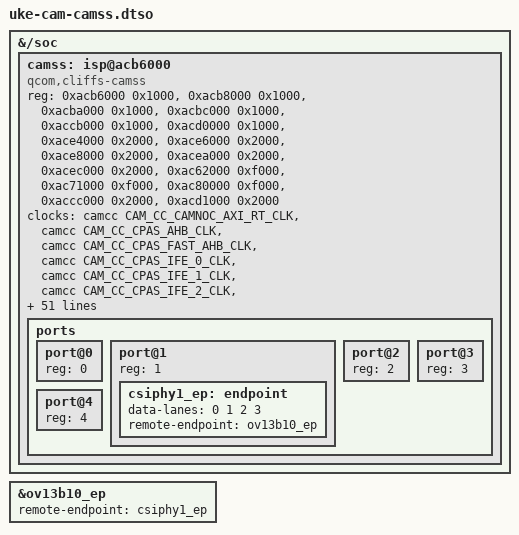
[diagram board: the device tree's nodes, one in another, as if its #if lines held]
// SPDX-License-Identifier: BSD-3-Clause
/*
 * uke-cam-camss.dtso -- C5: CAMSS (CSIPHY/CSID/VFE) de la uke con el driver mainline qcom-camss, recurso "qcom,cliffs-camss"
 * (copia parcheada: module/uke_camss, sin ICC y con 5 CSIPHY). Plan: CAMARAS-PLAN-20261019.md. C0, 19-oct-2026: compila y se aplica
 * con fdtoverlay (tras uke-cam-camcc y uke-cam-rear) en el PC; NO probado en la tablet.
 *
 * El mapa de la uke == el de sm8650 (medido, 19-oct): csid_wrapper acb6000; csid0/1/2 acb8000/acba000/acbc000; lite acca000->accb000,
 * acd0000; csiphy0..4 ace4000..acec000; vfe0/1/2 ac62000/ac71000/ac80000; IRQs SPI 601,603,431,605,376,477,478,479,448,122,602,604,688,606,377
 * (identicas a sm8650.dtsi); SMMU SIDs 0x800/0x20 (IFE), 0x18a0/0x40 (JPEG), 0x1860/0 (CDM). La uke NO tiene csiphy5 (acee000).
 * Sin `interconnects`: la capa ICC cliffs de senemos es solo USB/display (no hay MASTER_CAMNOC_HF) => el modulo parcheado usa 0 rutas ICC.
 * Enlace con el sensor: csiphy1 <-> ov13b10_ep (uke-cam-rear). Rieles CSIPHY = pmxr2230_l2 (0,9 V) y l4 (1,2 V) para los tres grupos.
 */
#include <dt-bindings/clock/qcom,gcc-cliffs.h>
#include <dt-bindings/clock/qcom,sm8650-camcc.h>
#include <dt-bindings/interrupt-controller/arm-gic.h>
#include <dt-bindings/interrupt-controller/irq.h>
/dts-v1/;
/plugin/;

/ {
	fragment@0 {
		target-path = "/soc";

		__overlay__ {
			camss: isp@acb6000 {
				compatible = "qcom,cliffs-camss";
				reg = <0xacb6000 0x1000>, <0xacb8000 0x1000>, <0xacba000 0x1000>, <0xacbc000 0x1000>,
				      <0xaccb000 0x1000>, <0xacd0000 0x1000>,
				      <0xace4000 0x2000>, <0xace6000 0x2000>, <0xace8000 0x2000>, <0xacea000 0x2000>, <0xacec000 0x2000>,
				      <0xac62000 0xf000>, <0xac71000 0xf000>, <0xac80000 0xf000>,
				      <0xaccc000 0x2000>, <0xacd1000 0x2000>;
				reg-names = "csid_wrapper", "csid0", "csid1", "csid2", "csid_lite0", "csid_lite1",
					    "csiphy0", "csiphy1", "csiphy2", "csiphy3", "csiphy4",
					    "vfe0", "vfe1", "vfe2", "vfe_lite0", "vfe_lite1";

				clocks = <&camcc CAM_CC_CAMNOC_AXI_RT_CLK>,
					 <&camcc CAM_CC_CPAS_AHB_CLK>,
					 <&camcc CAM_CC_CPAS_FAST_AHB_CLK>,
					 <&camcc CAM_CC_CPAS_IFE_0_CLK>,
					 <&camcc CAM_CC_CPAS_IFE_1_CLK>,
					 <&camcc CAM_CC_CPAS_IFE_2_CLK>,
					 <&camcc CAM_CC_CPAS_IFE_LITE_CLK>,
					 <&camcc CAM_CC_CSID_CLK>,
					 <&camcc CAM_CC_CSIPHY0_CLK>, <&camcc CAM_CC_CSI0PHYTIMER_CLK>,
					 <&camcc CAM_CC_CSIPHY1_CLK>, <&camcc CAM_CC_CSI1PHYTIMER_CLK>,
					 <&camcc CAM_CC_CSIPHY2_CLK>, <&camcc CAM_CC_CSI2PHYTIMER_CLK>,
					 <&camcc CAM_CC_CSIPHY3_CLK>, <&camcc CAM_CC_CSI3PHYTIMER_CLK>,
					 <&camcc CAM_CC_CSIPHY4_CLK>, <&camcc CAM_CC_CSI4PHYTIMER_CLK>,
					 <&camcc CAM_CC_CSID_CSIPHY_RX_CLK>,
					 <&gcc GCC_CAMERA_HF_AXI_CLK>,
					 <&camcc CAM_CC_QDSS_DEBUG_XO_CLK>,
					 <&camcc CAM_CC_IFE_0_CLK>, <&camcc CAM_CC_IFE_0_FAST_AHB_CLK>,
					 <&camcc CAM_CC_IFE_1_CLK>, <&camcc CAM_CC_IFE_1_FAST_AHB_CLK>,
					 <&camcc CAM_CC_IFE_2_CLK>, <&camcc CAM_CC_IFE_2_FAST_AHB_CLK>,
					 <&camcc CAM_CC_IFE_LITE_CLK>, <&camcc CAM_CC_IFE_LITE_AHB_CLK>,
					 <&camcc CAM_CC_IFE_LITE_CPHY_RX_CLK>, <&camcc CAM_CC_IFE_LITE_CSID_CLK>;
				clock-names = "camnoc_axi", "cpas_ahb", "cpas_fast_ahb",
					      "cpas_vfe0", "cpas_vfe1", "cpas_vfe2", "cpas_vfe_lite", "csid",
					      "csiphy0", "csiphy0_timer", "csiphy1", "csiphy1_timer",
					      "csiphy2", "csiphy2_timer", "csiphy3", "csiphy3_timer",
					      "csiphy4", "csiphy4_timer", "csiphy_rx", "gcc_axi_hf", "qdss_debug_xo",
					      "vfe0", "vfe0_fast_ahb", "vfe1", "vfe1_fast_ahb", "vfe2", "vfe2_fast_ahb",
					      "vfe_lite", "vfe_lite_ahb", "vfe_lite_cphy_rx", "vfe_lite_csid";

				interrupts = <GIC_SPI 601 IRQ_TYPE_EDGE_RISING>, <GIC_SPI 603 IRQ_TYPE_EDGE_RISING>,
					     <GIC_SPI 431 IRQ_TYPE_EDGE_RISING>, <GIC_SPI 605 IRQ_TYPE_EDGE_RISING>,
					     <GIC_SPI 376 IRQ_TYPE_EDGE_RISING>,
					     <GIC_SPI 477 IRQ_TYPE_EDGE_RISING>, <GIC_SPI 478 IRQ_TYPE_EDGE_RISING>,
					     <GIC_SPI 479 IRQ_TYPE_EDGE_RISING>, <GIC_SPI 448 IRQ_TYPE_EDGE_RISING>,
					     <GIC_SPI 122 IRQ_TYPE_EDGE_RISING>,
					     <GIC_SPI 602 IRQ_TYPE_EDGE_RISING>, <GIC_SPI 604 IRQ_TYPE_EDGE_RISING>,
					     <GIC_SPI 688 IRQ_TYPE_EDGE_RISING>, <GIC_SPI 606 IRQ_TYPE_EDGE_RISING>,
					     <GIC_SPI 377 IRQ_TYPE_EDGE_RISING>;
				interrupt-names = "csid0", "csid1", "csid2", "csid_lite0", "csid_lite1",
						  "csiphy0", "csiphy1", "csiphy2", "csiphy3", "csiphy4",
						  "vfe0", "vfe1", "vfe2", "vfe_lite0", "vfe_lite1";

#ifdef WITH_IOMMU
				/* C5b: EXIGE el kernel con patches/0046 (SID del IFE en la allowlist del SMMU + su ACTLR). Solo el IFE: fwspec id =
				 * sid | mask<<16 = 0x200800. JPEG (0x18a0, ACTLR 0x103) y CDM (0x1860) NO se piden: no hacen falta para RDI en RAW. */
				iommus = <&apps_smmu 0x800 0x20>;
#endif /* C5a (por defecto): sin iommus => camss prueba topologia/relojes/GDSC sin DMA (no hay trafico por el SMMU) */

				power-domains = <&camcc CAM_CC_IFE_0_GDSC>, <&camcc CAM_CC_IFE_1_GDSC>,
						<&camcc CAM_CC_IFE_2_GDSC>, <&camcc CAM_CC_TITAN_TOP_GDSC>;
				power-domain-names = "ife0", "ife1", "ife2", "top";

				vdd-csiphy01-0p9-supply = <&pmxr2230_l2>;
				vdd-csiphy01-1p2-supply = <&pmxr2230_l4>;
				vdd-csiphy24-0p9-supply = <&pmxr2230_l2>;
				vdd-csiphy24-1p2-supply = <&pmxr2230_l4>;
				vdd-csiphy35-0p9-supply = <&pmxr2230_l2>;
				vdd-csiphy35-1p2-supply = <&pmxr2230_l4>;

				ports {
					#address-cells = <1>;
					#size-cells = <0>;

					port@0 { reg = <0>; };
					port@1 {
						reg = <1>;
						csiphy1_ep: endpoint {
							data-lanes = <0 1 2 3>;	/* camss numera las posiciones del PHY desde 0: con <1 2 3 4> CTRL5=0xd4 (C5b: «uke-phy: data_pos=1,2,3,4»); Android: lane_enable 0xd5, lane_assign 0x3210 */
							remote-endpoint = <&ov13b10_ep>;
						};
					};
					port@2 { reg = <2>; };
					port@3 { reg = <3>; };
					port@4 { reg = <4>; };
				};
			};
		};
	};

	fragment@1 {
		target = <&ov13b10_ep>;

		__overlay__ {
			remote-endpoint = <&csiphy1_ep>;
		};
	};
};
